# TLE984x register map
Vendor: Infineon Technologies AG; File version: 1.6
CPU: CM0 r0p0, little endian, no MPU, no FPU, 2 interrupt priority bits
Registers are 32-bit, read-write, no defined reset value unless marked. A register's access mark holds for its fields unless they carry their own. Offsets are from the block's base; [hi:lo] are bit positions; 'fields as' and 'values as' point back to an identical list.

## SCUPM
Base 0x50006000
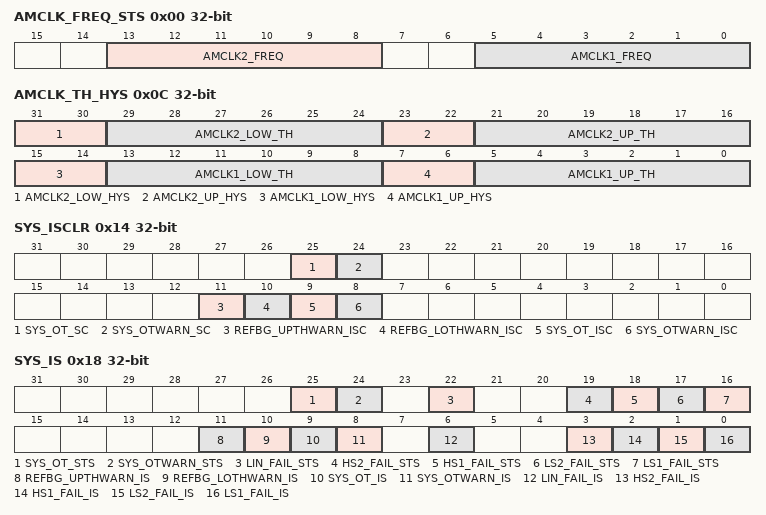
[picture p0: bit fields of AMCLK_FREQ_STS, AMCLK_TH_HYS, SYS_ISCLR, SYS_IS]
0x00 AMCLK_FREQ_STS ro — Analog Module Clock Frequency Status Register
  [13:8] AMCLK2_FREQ — Current frequency of Analog Module Clock 2 (TFILT_CLK)
  [5:0] AMCLK1_FREQ — Current frequency of Analog Module Clock System Clock (MI_CLK)
0x04 AMCLK_CTRL — Analog Module Clock Control Register
  [0] CLKWDT_PD_N — Clock Watchdog Powerdown
    0=DISABLE (Clock Watchdog disabled); 1=ENABLE (Clock Watchdog enabled)
0x0C AMCLK_TH_HYS — Analog Module Clock Limit Register
  [31:30] AMCLK2_LOW_HYS — Analog Module Clock 2 (TFILT_CLK) Lower Hysteresis
  [29:24] AMCLK2_LOW_TH — Analog Module Clock 2 (TFILT_CLK) Lower Limit Threshold
  [23:22] AMCLK2_UP_HYS — Analog Module Clock 2 (TFILT_CLK) Upper Hysteresis
  [21:16] AMCLK2_UP_TH — Analog Module Clock 2 (TFILT_CLK) Upper Limit Threshold
  [15:14] AMCLK1_LOW_HYS — Analog Module Clock 1 (MI_CLK) Lower Hysteresis
  [13:8] AMCLK1_LOW_TH — Analog Module Clock 1 (MI_CLK) Lower Limit Threshold
  [7:6] AMCLK1_UP_HYS — Analog Module Clock 1 (MI_CLK) Upper Hysteresis
  [5:0] AMCLK1_UP_TH — Analog Module Clock 1 (MI_CLK) Upper Limit Threshold
0x14 SYS_ISCLR wo — System Interrupt Status Clear Register
  [25] SYS_OT_SC — System Overtemperature Shutdown status clear
    0=No Clear; 1=Clear
  [24] SYS_OTWARN_SC — System Overtemperature Prewarning status clear
    0=No CLear; 1=Clear
  [11] REFBG_UPTHWARN_ISC — 8-Bit ADC2 Reference Overvoltage interrupt status clear
    0=No Clear; 1=Clear
  [10] REFBG_LOTHWARN_ISC — 8-Bit ADC2 Reference Undervoltage interrupt status clear
    0=No Clear; 1=Clear
  [9] SYS_OT_ISC — System Overtemperature Shutdown status clear
    0=No Clear; 1=Clear
  [8] SYS_OTWARN_ISC — System Overtemperature Prewarning status clear
    0=No Clear; 1=Clear
0x18 SYS_IS access per field — System Interrupt Status Register
  [25] SYS_OT_STS rw — System Overtemperature Shutdown (ADC2, Channel 6) status
    0=INACTIVE (no status set); 1=ACTIVE (at least one status set)
  [24] SYS_OTWARN_STS rw — System Overtemperature Prewarning (ADC2, Channel 6) status
    values as SYS_OT_STS
  [22] LIN_FAIL_STS ro — LIN Fail Status
    values as SYS_OT_STS
  [19] HS2_FAIL_STS ro — High Side Driver 2 Fail Status
    values as SYS_OT_STS
  [18] HS1_FAIL_STS ro — High Side Driver 1 Fail Status
    values as SYS_OT_STS
  [17] LS2_FAIL_STS ro — Low Side Driver 2 Fail Status
    values as SYS_OT_STS
  [16] LS1_FAIL_STS ro — Low Side Driver 1 Fail Status
    values as SYS_OT_STS
  [11] REFBG_UPTHWARN_IS rw — 8-Bit ADC2 Reference Overvoltage (ADC2, Channel 3) interrupt status
    0=INACTIVE (no interrupt status set); 1=ACTIVE (at least one interrupt status set)
  [10] REFBG_LOTHWARN_IS rw — 8-Bit ADC2 Reference Undervoltage (ADC2, Channel 3) interrupt status
    values as REFBG_UPTHWARN_IS
  [9] SYS_OT_IS rw — System Overtemperature Shutdown (ADC2, Channel 6) interrupt status
    values as REFBG_UPTHWARN_IS
  [8] SYS_OTWARN_IS rw — System Overtemperature Prewarning (ADC2, Channel 6) interrupt status
    values as REFBG_UPTHWARN_IS
  [6] LIN_FAIL_IS ro — LIN Fail Interrupt Status
    values as SYS_OT_STS
  [3] HS2_FAIL_IS ro — High Side Driver 2 Fail Interrupt Status
    values as SYS_OT_STS
  [2] HS1_FAIL_IS ro — High Side Driver 1 Fail Interrupt Status
    values as SYS_OT_STS
  [1] LS2_FAIL_IS ro — Low Side Driver 2 Fail Interrupt Status
    values as SYS_OT_STS
  [0] LS1_FAIL_IS ro — Low Side Driver 1 Fail Interrupt Status
    values as SYS_OT_STS
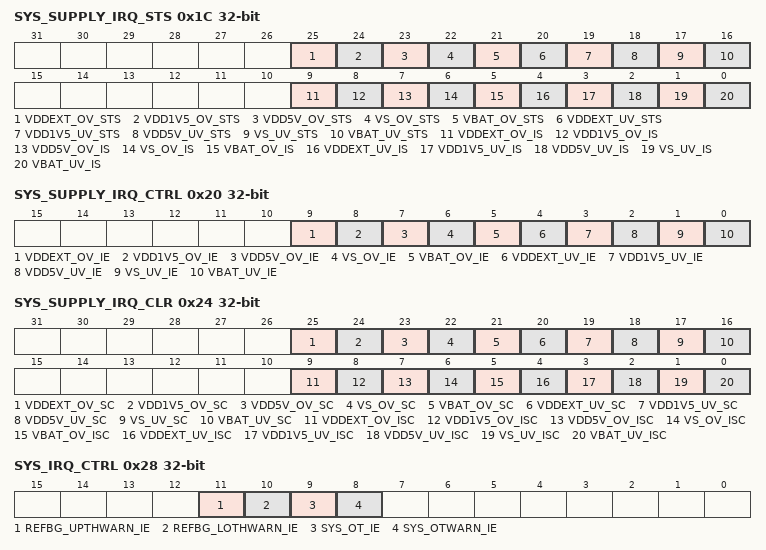
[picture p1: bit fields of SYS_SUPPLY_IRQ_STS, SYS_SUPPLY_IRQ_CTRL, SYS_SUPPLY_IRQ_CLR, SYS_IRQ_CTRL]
0x1C SYS_SUPPLY_IRQ_STS — System Supply Interrupt Status Register
  [25] VDDEXT_OV_STS — VDDEXT Overvoltage Status
    0=No Overvoltage (occurred); 1=Overvoltage (occurred)
  [24] VDD1V5_OV_STS — VDDC Overvoltage Status
    0=No Overvoltage (occurred); 1=Overvoltage (occurred)
  [23] VDD5V_OV_STS — VDDP Overvoltage Status
    0=No Overvoltage (occurred); 1=Overvoltage (occurred)
  [22] VS_OV_STS — VS Overvoltage Status
    0=No Overvoltage (occurred); 1=Overvoltage (occurred)
  [21] VBAT_OV_STS — VBAT Overvoltage Status
    0=No Overvoltage (occurred); 1=Overvoltage (occurred)
  [20] VDDEXT_UV_STS — VDDEXT Undervoltage Status
    0=No Undervoltage (occurred); 1=Undervoltage (occurred)
  [19] VDD1V5_UV_STS — VDDC Undervoltage Status
    0=No Undervoltage (occurred); 1=Undervoltage (occurred)
  [18] VDD5V_UV_STS — VDDP Undervoltage Status
    0=No Undervoltage (occurred); 1=Undervoltage (occurred)
  [17] VS_UV_STS — VS Undervoltage Status
    0=No Undervoltage (occurred); 1=Undervoltage (occurred)
  [16] VBAT_UV_STS — VBAT Undervoltage Status
    0=No Undervoltage (occurred); 1=Undervoltage (occurred)
  [9] VDDEXT_OV_IS — VDDEXT Overvoltage Interrupt Status
    0=No Overvoltage Interrupt (occurred); 1=Overvoltage Interrupt (occurred)
  [8] VDD1V5_OV_IS — VDDC Overvoltage Interrupt Status
    values as VDDEXT_OV_IS
  [7] VDD5V_OV_IS — VDDP Overvoltage Interrupt Status
    values as VDDEXT_OV_IS
  [6] VS_OV_IS — VS Overvoltage Interrupt Status
    values as VDDEXT_OV_IS
  [5] VBAT_OV_IS — VBAT Overvoltage Interrupt Status
    values as VDDEXT_OV_IS
  [4] VDDEXT_UV_IS — VDDEXT Undervoltage Interrupt Status
    0=No Undervoltage Interrupt (occurred); 1=Undervoltage Interrupt (occurred)
  [3] VDD1V5_UV_IS — VDDC Undervoltage Interrupt Status
    values as VDDEXT_UV_IS
  [2] VDD5V_UV_IS — VDDP Undervoltage Interrupt Status
    values as VDDEXT_UV_IS
  [1] VS_UV_IS — VS Undervoltage Interrupt Status
    values as VDDEXT_UV_IS
  [0] VBAT_UV_IS — VBAT Undervoltage Interrupt Status
    values as VDDEXT_UV_IS
0x20 SYS_SUPPLY_IRQ_CTRL — System Supply Interrupt Control Register
  [all] fields
    0=Interrupt is disabled; 1=Interrupt is enabled
  [9] VDDEXT_OV_IE — VDDEXT Overvoltage Interrupt Enable
  [8] VDD1V5_OV_IE — VDDC Overvoltage Interrupt Enable
  [7] VDD5V_OV_IE — VDDP Overvoltage Interrupt Enable
  [6] VS_OV_IE — VS Overvoltage Interrupt Enable
  [5] VBAT_OV_IE — VBAT Overvoltage Interrupt Enable
  [4] VDDEXT_UV_IE — VDDEXT Undervoltage Interrupt Enable
  [3] VDD1V5_UV_IE — VDDC Undervoltage Interrupt Enable
  [2] VDD5V_UV_IE — VDDP Undervoltage Interrupt Enable
  [1] VS_UV_IE — VS Undervoltage Interrupt Enable
  [0] VBAT_UV_IE — VBAT Undervoltage Interrupt Enable
0x24 SYS_SUPPLY_IRQ_CLR wo — System Supply Interrupt Status Clear Register
  [all] fields
    0=No Clear; 1=Clear
  [25] VDDEXT_OV_SC — VDDEXT Overvoltage Status clear
  [24] VDD1V5_OV_SC — VDDC Overvoltage Status clear
  [23] VDD5V_OV_SC — VDDP Overvoltage Status clear
  [22] VS_OV_SC — VS Overvoltage Status clear
  [21] VBAT_OV_SC — VBAT Overvoltage Status clear
  [20] VDDEXT_UV_SC — VDDEXT Undervoltage Status clear
  [19] VDD1V5_UV_SC — VDDC Undervoltage Status clear
  [18] VDD5V_UV_SC — VDDP Undervoltage Status clear
  [17] VS_UV_SC — VS Undervoltage Status clear
  [16] VBAT_UV_SC — VBAT Undervoltage Status clear
  [9] VDDEXT_OV_ISC — VDDEXT Overvoltage Interrupt Status clear
  [8] VDD1V5_OV_ISC — VDDC Overvoltage Interrupt Status clear
  [7] VDD5V_OV_ISC — VDDP Overvoltage Interrupt Status clear
  [6] VS_OV_ISC — VS Overvoltage Interrupt Status clear
  [5] VBAT_OV_ISC — VBAT Overvoltage Interrupt Status clear
  [4] VDDEXT_UV_ISC — VDDEXT Undervoltage Interrupt Status clear
  [3] VDD1V5_UV_ISC — VDDC Undervoltage Interrupt Status clear
  [2] VDD5V_UV_ISC — VDDP Undervoltage Interrupt Status clear
  [1] VS_UV_ISC — VS Undervoltage Interrupt Status clear
  [0] VBAT_UV_ISC — VBAT Undervoltage Interrupt Status clear
0x28 SYS_IRQ_CTRL — System Interrupt Control Register
  [all] fields
    0=Interrupt is disabled; 1=Interrupt is enabled
  [11] REFBG_UPTHWARN_IE — Reference Voltage Overvoltage Interrupt Enable
  [10] REFBG_LOTHWARN_IE — Reference Voltage Undervoltage Interrupt Enable
  [9] SYS_OT_IE — System Overtemperature Shutdown Interrupt Enable (leads to shutdown of System)
  [8] SYS_OTWARN_IE — System Overtemperature Warning Interrupt Enable
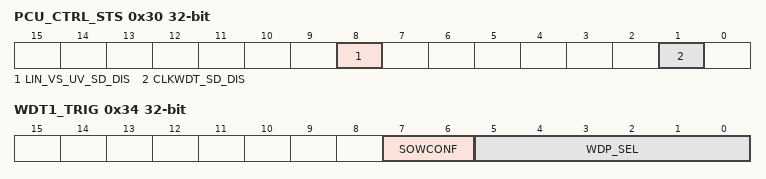
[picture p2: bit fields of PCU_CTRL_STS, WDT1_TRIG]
0x30 PCU_CTRL_STS — Power Control Unit Control Status Register
  [8] LIN_VS_UV_SD_DIS — LIN Module VS Undervoltage Transmitter Shutdown
    0=Enable (Automatic Shutdown for Power modules in case of VS Undervoltage enabled); 1=Disable (Automatic Shutdown for Power modules in case of VS Undervoltage disabled)
  [1] CLKWDT_SD_DIS — Power Modules Clock Watchdog Shutdown Disable
    0=Shutdown Enable (Power Devices will be switched off when Clock Watchdog occurs); 1=Shutdown Disable (Power Devices will not be shutdown when Clock Watchdog occurs)
0x34 WDT1_TRIG — WDT1 Watchdog Control
  [7:6] SOWCONF — Short Open Window Configuration
    0=DIS (Short Open Windows disabled); 1=SOW1 (one successive Short Open Window allowed); 2=SOW2 (two successive Short Open Windows allowed); 3=SOW3 (three successive Short Open Windows allowed)
  [5:0] WDP_SEL — Watchdog Period Selection and trigger
    0=SOW_TRIG (trigger short open window); 1=WP_1 (Watchdog period 16 ms); 2=WP_2 (Watchdog period 32 ms); 3=WP_3 (Watchdog period 48 ms); 63=WP_63 (Watchdog period 1008 ms)
0x6C STCALIB — System Tick Calibration Register
  [25:0] STCALIB — System Tick Calibration
